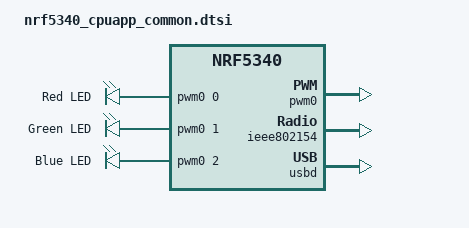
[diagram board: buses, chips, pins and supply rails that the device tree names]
/*
 * Copyright (c) 2019-2020 Nordic Semiconductor ASA
 *
 * SPDX-License-Identifier: Apache-2.0
 */
#include "bmd100_common.dtsi"
#include "nrf5340_cpuapp_common-pinctrl.dtsi"
#include <zephyr/dt-bindings/input/input-event-codes.h>

/ {

	chosen {
		zephyr,bt-hci = &bt_hci_ipc0;
		nordic,802154-spinel-ipc = &ipc0;
		zephyr,ieee802154 = &ieee802154;
	};

	/**
	* https://developer.nordicsemi.com/nRF_Connect_SDK/doc/2.1.0-rc2/zephyr/build/dts/api/bindings/gpio/nordic%2Cnrf-gpio-forwarder.html
	*/
	gpio_fwd: nrf-gpio-forwarder {
		compatible = "nordic,nrf-gpio-forwarder";
		status = "okay";
		fem-gpio-if {
			gpios =	<&gpio0 30 0>, /* tx-en-gpios */
					<&gpio0 31 0>, /* rx-en-gpios */
					<&gpio1 10 0>, /* pdn-gpios */
					<&gpio1 13 0>; /* mode-gpios */
		};
		spi_fwd {
			gpios = <&gpio1 8 0>,	/* cs-gpios */
					<&gpio0 29 0>,	/* SPIM_SCK */
					<&gpio0 24 0>,	/* SPIM_MISO */
					<&gpio0 26 0>;	/* SPIM_MOSI */
		};
	};

	/* The RGB LED again, on PWM for dimming. Same pins as led0-led2. */
	pwmleds {
		compatible = "pwm-leds";

		pwm_led0: pwm_led_0 {
			pwms = <&pwm0 0 PWM_MSEC(1) PWM_POLARITY_INVERTED>;
			label = "Red LED";
		};
		pwm_led1: pwm_led_1 {
			pwms = <&pwm0 1 PWM_MSEC(1) PWM_POLARITY_INVERTED>;
			label = "Green LED";
		};
		pwm_led2: pwm_led_2 {
			pwms = <&pwm0 2 PWM_MSEC(1) PWM_POLARITY_INVERTED>;
			label = "Blue LED";
		};
	};

	aliases {
		pwm-led0 = &pwm_led0;
		pwm-led1 = &pwm_led1;
		pwm-led2 = &pwm_led2;
	};
};

&pwm0 {
	status = "okay";
	pinctrl-0 = <&pwm0_default>;
	pinctrl-1 = <&pwm0_sleep>;
	pinctrl-names = "default", "sleep";
};

&gpiote {
	status = "okay";
};

&gpio0 {
	status = "okay";
};

&gpio1 {
	status = "okay";
};

&uicr {
	nfct-pins-as-gpios;
};

&ieee802154 {
	status = "okay";
};

zephyr_udc0: &usbd {
	compatible = "nordic,nrf-usbd";
	status = "okay";
};
